# STM32F407Test register map
File version: 1.0
CPU: CM0+ r0p1, little endian, MPU, no FPU, 4 interrupt priority bits
Registers are 32-bit, read-write, reset 0x0 unless marked. A register's access mark holds for its fields unless they carry their own. Offsets are from the block's base; [hi:lo] are bit positions.

## CRC — CRC calculation unit
Base 0x40023000
0x00 DR — CRC data register
0x04 IDR — CRC independent data register
  [7:0] IDR
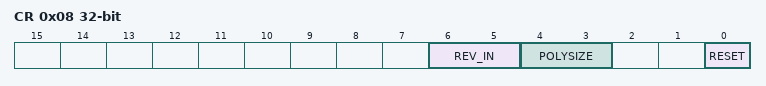
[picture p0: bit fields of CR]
0x08 CR — CRC control register
  [6:5] REV_IN, [4:3] POLYSIZE, [0] RESET

## RCC — Reset and clock control
Base 0x40023800
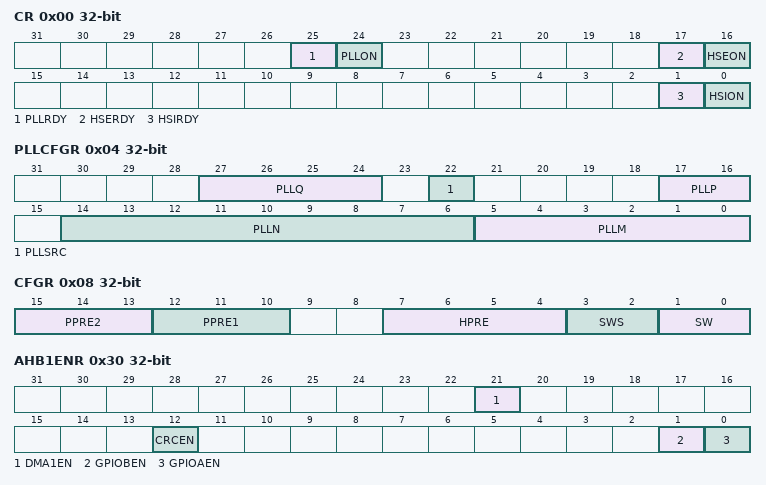
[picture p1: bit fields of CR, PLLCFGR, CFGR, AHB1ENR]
0x00 CR — Clock control register
  [25] PLLRDY, [24] PLLON, [17] HSERDY, [16] HSEON, [1] HSIRDY, [0] HSION
0x04 PLLCFGR — PLL configuration register
  [27:24] PLLQ, [22] PLLSRC, [17:16] PLLP, [14:6] PLLN, [5:0] PLLM
0x08 CFGR — Clock configuration register
  [15:13] PPRE2, [12:10] PPRE1, [7:4] HPRE, [3:2] SWS, [1:0] SW
0x30 AHB1ENR — AHB1 peripheral clock enable
  [21] DMA1EN, [12] CRCEN, [1] GPIOBEN, [0] GPIOAEN
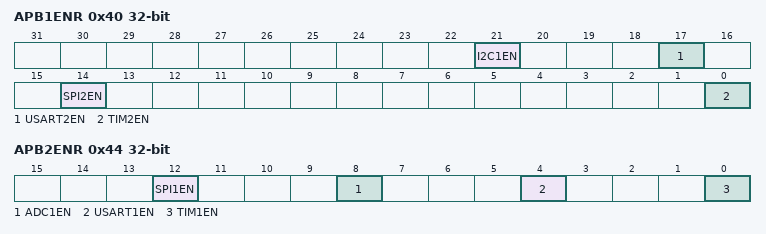
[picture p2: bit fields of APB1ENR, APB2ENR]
0x40 APB1ENR — APB1 peripheral clock enable
  [21] I2C1EN, [17] USART2EN, [14] SPI2EN, [0] TIM2EN
0x44 APB2ENR — APB2 peripheral clock enable
  [12] SPI1EN, [8] ADC1EN, [4] USART1EN, [0] TIM1EN

## TIM1 — Advanced-control timer 1
Base 0x40010000
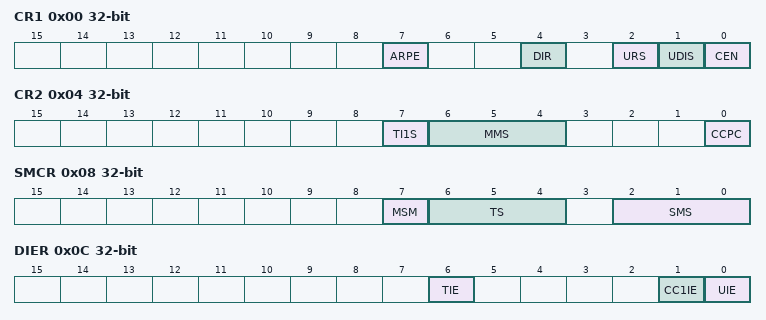
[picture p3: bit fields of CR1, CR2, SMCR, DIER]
0x00 CR1 — Control register 1
  [7] ARPE, [4] DIR, [2] URS, [1] UDIS, [0] CEN
0x04 CR2 — Control register 2
  [7] TI1S, [6:4] MMS, [0] CCPC
0x08 SMCR — Slave mode control register
  [7] MSM, [6:4] TS, [2:0] SMS
0x0C DIER — DMA/interrupt enable register
  [6] TIE, [1] CC1IE, [0] UIE
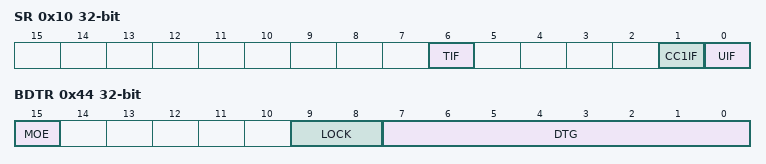
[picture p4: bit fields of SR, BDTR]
0x10 SR — Status register
  [6] TIF, [1] CC1IF, [0] UIF
0x28 PSC — Prescaler
  [15:0] PSC
0x2C ARR — Auto-reload register
  [15:0] ARR
0x34 CCR1 — Capture/compare register 1
  [15:0] CCR1
0x44 BDTR — Break and dead-time register
  [15] MOE, [9:8] LOCK, [7:0] DTG

## TIM2 — General-purpose timer 2
Base 0x40000000
Same registers: TIM3 0x40000400, TIM4 0x40000800, TIM5 0x40000C00, TIM9 0x40014000, TIM10 0x40014400, TIM11 0x40014800
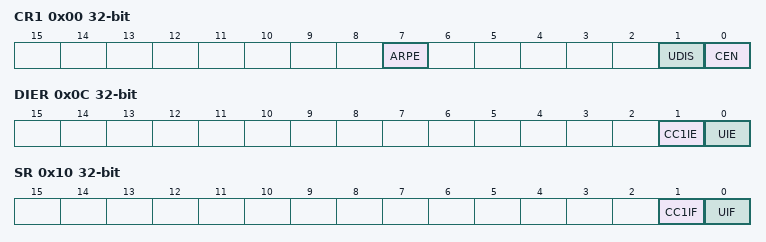
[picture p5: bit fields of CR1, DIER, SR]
0x00 CR1 — Control register 1
  [7] ARPE, [1] UDIS, [0] CEN
0x0C DIER — DMA/interrupt enable register
  [1] CC1IE, [0] UIE
0x10 SR — Status register
  [1] CC1IF, [0] UIF
0x28 PSC — Prescaler
  [15:0] PSC
0x2C ARR — Auto-reload register

## USART1
Base 0x40011000
Same registers: USART2 0x40004400, USART3 0x40004800, UART4 0x40004C00, UART5 0x40005000, USART6 0x40011400
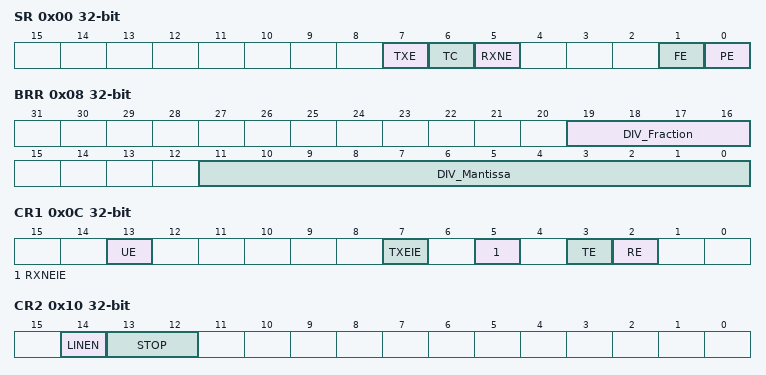
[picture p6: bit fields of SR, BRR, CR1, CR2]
0x00 SR — Status register
  [7] TXE, [6] TC, [5] RXNE, [1] FE, [0] PE
0x04 DR — Data register
  [8:0] DR
0x08 BRR — Baud rate register
  [19:16] DIV_Fraction, [11:0] DIV_Mantissa
0x0C CR1 — Control register 1
  [13] UE, [7] TXEIE, [5] RXNEIE, [3] TE, [2] RE
0x10 CR2 — Control register 2
  [14] LINEN, [13:12] STOP
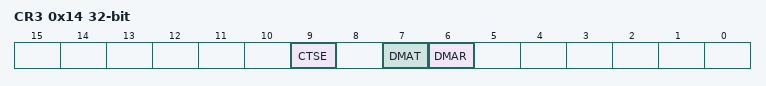
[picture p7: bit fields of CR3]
0x14 CR3 — Control register 3
  [9] CTSE, [7] DMAT, [6] DMAR

## SPI1
Base 0x40013000
Same registers: SPI2 0x40003800, SPI3 0x40003C00
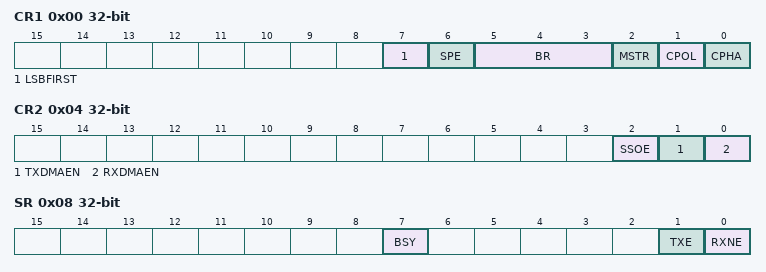
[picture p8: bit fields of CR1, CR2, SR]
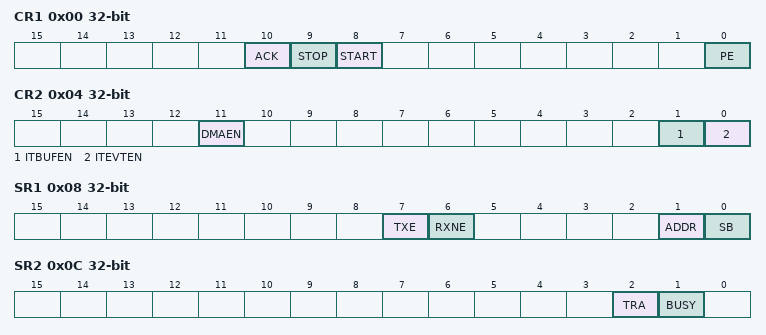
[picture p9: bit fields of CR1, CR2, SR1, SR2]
0x00 CR1 — Control register 1
  [7] LSBFIRST, [6] SPE, [5:3] BR, [2] MSTR, [1] CPOL, [0] CPHA
0x04 CR2 — Control register 2
  [2] SSOE, [1] TXDMAEN, [0] RXDMAEN
0x08 SR — Status register
  [7] BSY, [1] TXE, [0] RXNE
0x0C DR — Data register
  [15:0] DR

## I2C1
Base 0x40005400
Same registers: I2C2 0x40005800, I2C3 0x40005C00
0x00 CR1 — Control register 1
  [10] ACK, [9] STOP, [8] START, [0] PE
0x04 CR2 — Control register 2
  [11] DMAEN, [1] ITBUFEN, [0] ITEVTEN
0x08 SR1 — Status register 1
  [7] TXE, [6] RXNE, [1] ADDR, [0] SB
0x0C SR2 — Status register 2
  [2] TRA, [1] BUSY
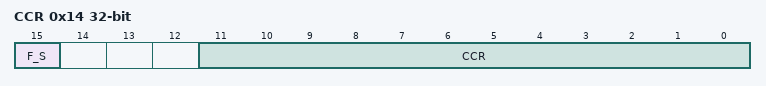
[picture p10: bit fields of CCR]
0x14 CCR — Clock control register
  [15] F_S, [11:0] CCR

## ADC1
Base 0x40012000
Same registers: ADC2 0x40012100, ADC3 0x40012200
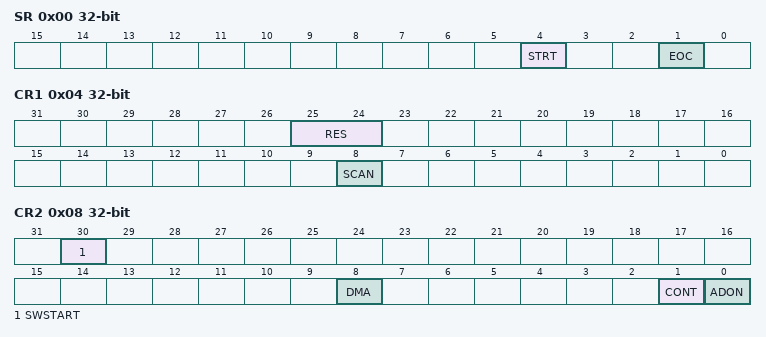
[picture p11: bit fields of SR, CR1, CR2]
0x00 SR — Status register
  [4] STRT, [1] EOC
0x04 CR1 — Control register 1
  [25:24] RES, [8] SCAN
0x08 CR2 — Control register 2
  [30] SWSTART, [8] DMA, [1] CONT, [0] ADON
0x4C DR — Regular data register
  [15:0] DATA

## DAC — Digital-to-analog converter
Base 0x40007400
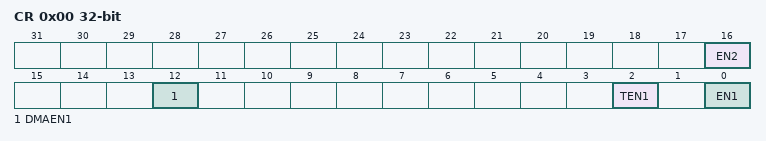
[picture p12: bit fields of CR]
0x00 CR — Control register
  [16] EN2, [12] DMAEN1, [2] TEN1, [0] EN1
0x08 DHR12R1 — Channel 1 12-bit data
  [11:0] DACC1DHR
0x2C DOR1 — Channel 1 data output
  [11:0] DACC1DOR

## SYSCFG — System configuration controller
Base 0x40013800
0x00 MEMRMP — Memory remap register
  [1:0] MEM_MODE
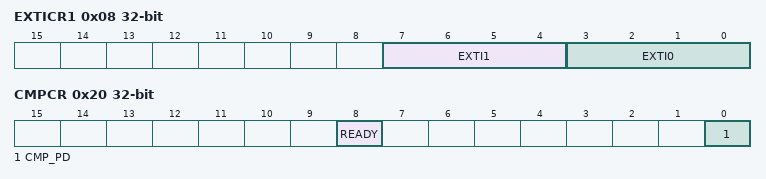
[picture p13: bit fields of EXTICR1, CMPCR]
0x08 EXTICR1 — External interrupt config 1
  [7:4] EXTI1, [3:0] EXTI0
0x20 CMPCR — Compensation cell control
  [8] READY, [0] CMP_PD

## EXTI — External interrupt/event controller
Base 0x40013C00
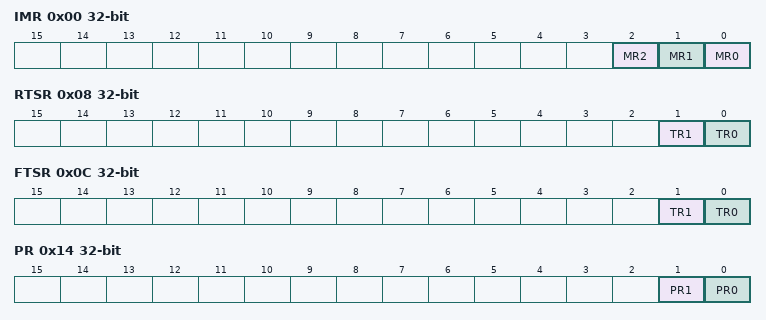
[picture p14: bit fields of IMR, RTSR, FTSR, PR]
0x00 IMR — Interrupt mask register
  [2] MR2, [1] MR1, [0] MR0
0x08 RTSR — Rising trigger selection
  [1] TR1, [0] TR0
0x0C FTSR — Falling trigger selection
  [1] TR1, [0] TR0
0x14 PR — Pending register
  [1] PR1, [0] PR0

## NVIC — Nested vectored interrupt controller
Base 0xE000E100
0x00 ISER0 — Interrupt set-enable 0
  [31:0] SETENA
0x80 ICER0 — Interrupt clear-enable 0
  [31:0] CLRENA
0x100 ISPR0 — Interrupt set-pending 0
  [31:0] SETPEND

## SCB — System control block
Base 0xE000ED00
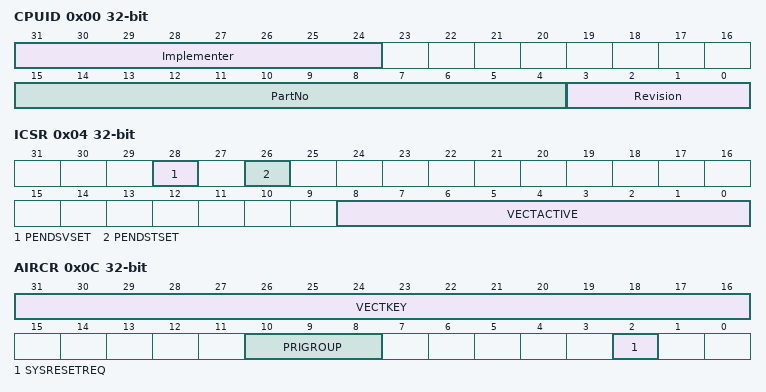
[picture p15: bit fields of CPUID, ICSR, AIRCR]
0x00 CPUID — CPUID base register
  [31:24] Implementer, [15:4] PartNo, [3:0] Revision
0x04 ICSR — Interrupt control state
  [28] PENDSVSET, [26] PENDSTSET, [8:0] VECTACTIVE
0x0C AIRCR — Application interrupt reset control
  [31:16] VECTKEY, [10:8] PRIGROUP, [2] SYSRESETREQ

## FLASH — Flash memory interface
Base 0x40023C00
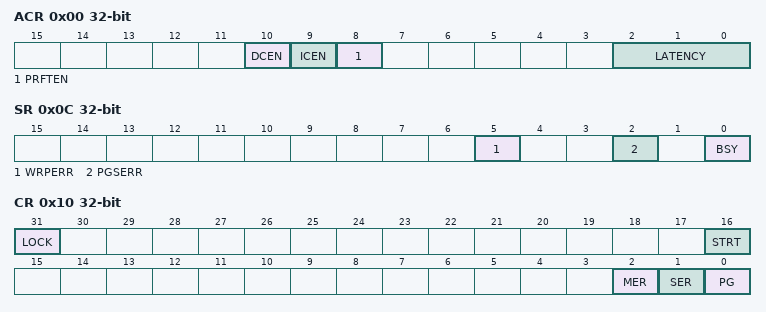
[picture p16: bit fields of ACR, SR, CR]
0x00 ACR — Flash access control
  [10] DCEN, [9] ICEN, [8] PRFTEN, [2:0] LATENCY
0x0C SR — Flash status register
  [5] WRPERR, [2] PGSERR, [0] BSY
0x10 CR — Flash control register
  [31] LOCK, [16] STRT, [2] MER, [1] SER, [0] PG

## PWR — Power controller
Base 0x40007000
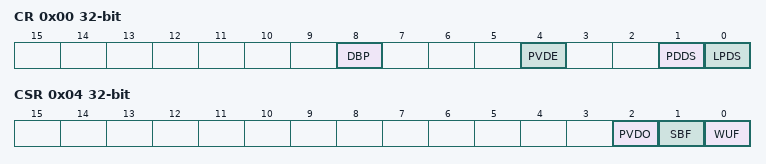
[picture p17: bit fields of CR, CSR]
0x00 CR — Power control register
  [8] DBP, [4] PVDE, [1] PDDS, [0] LPDS
0x04 CSR — Power status register
  [2] PVDO, [1] SBF, [0] WUF

## RTC — Real-time clock
Base 0x40002800
0x00 TR — Time register
  [19:16] HU, [11:8] MNU, [6:4] ST, [3:0] SU
0x04 DR — Date register
  [19:16] YU, [11:8] MU, [3:0] DU
0x08 CR — Control register
  [6] FMT
0x0C ISR — Init and status register
  [7] INIT, [3] RSF
0x10 PRER — Prescaler register
  [22:16] PREDIV_A, [14:0] PREDIV_S

## IWDG — Independent watchdog
Base 0x40003000
0x00 KR — Key register
  [15:0] KEY
0x04 PR — Prescaler register
  [2:0] PR
0x08 RLR — Reload register
  [11:0] RL
0x0C SR — Status register
  [1] RVU, [0] PVU

## WWDG — Window watchdog
Base 0x40002C00
0x00 CR — Control register
  [7] WDGA, [6:0] T
0x04 CFR — Configuration register
  [9] EWI, [8:7] WDGTB, [6:0] W
0x08 SR — Status register
  [0] EWIF

## CAN1
Base 0x40006400
Same registers: CAN2 0x40006800
0x00 MCR — Master control register
  [6] ABOM, [4] NART, [1] SLEEP, [0] INRQ
0x04 MSR — Master status register
  [2] ERRI, [1] SLAK, [0] INAK
0x1C BTR — Bit timing register
  [22:20] TS2, [19:16] TS1, [9:0] BRP

## OTG_FS — USB OTG full speed
Base 0x50000000
0x00 GOTGCTL — OTG control
  [9] HNPRQ, [0] SRQSCS
0x08 GAHBCFG — AHB configuration
  [0] GINT
0x0C GUSBCFG — USB configuration
  [30] FDMOD, [6] PHYSEL

## ETHERNET_MAC
Base 0x40028000
0x00 MACCR — MAC configuration
  [11] DM, [3] TE, [2] RE
0x10 MACMIIAR — MAC MII address
  [15:11] PA, [10:6] MR
0x14 MACMIIDR — MAC MII data
  [15:0] MD

## RNG — Random number generator
Base 0x50060800
0x00 CR — Control register
  [3] IE, [2] RNGEN
0x04 SR — Status register
  [2] SECS, [1] CECS, [0] DRDY
0x08 DR — Data register
  [31:0] RNDATA

## DBGMCU — Debug MCU
Base 0xE0042000
0x00 IDCODE — Device identifier
  [31:16] REV_ID, [11:0] DEV_ID
0x04 CR — Debug configuration
  [6:5] TRACE_IOEN, [1] DBG_STOP, [0] DBG_SLEEP
